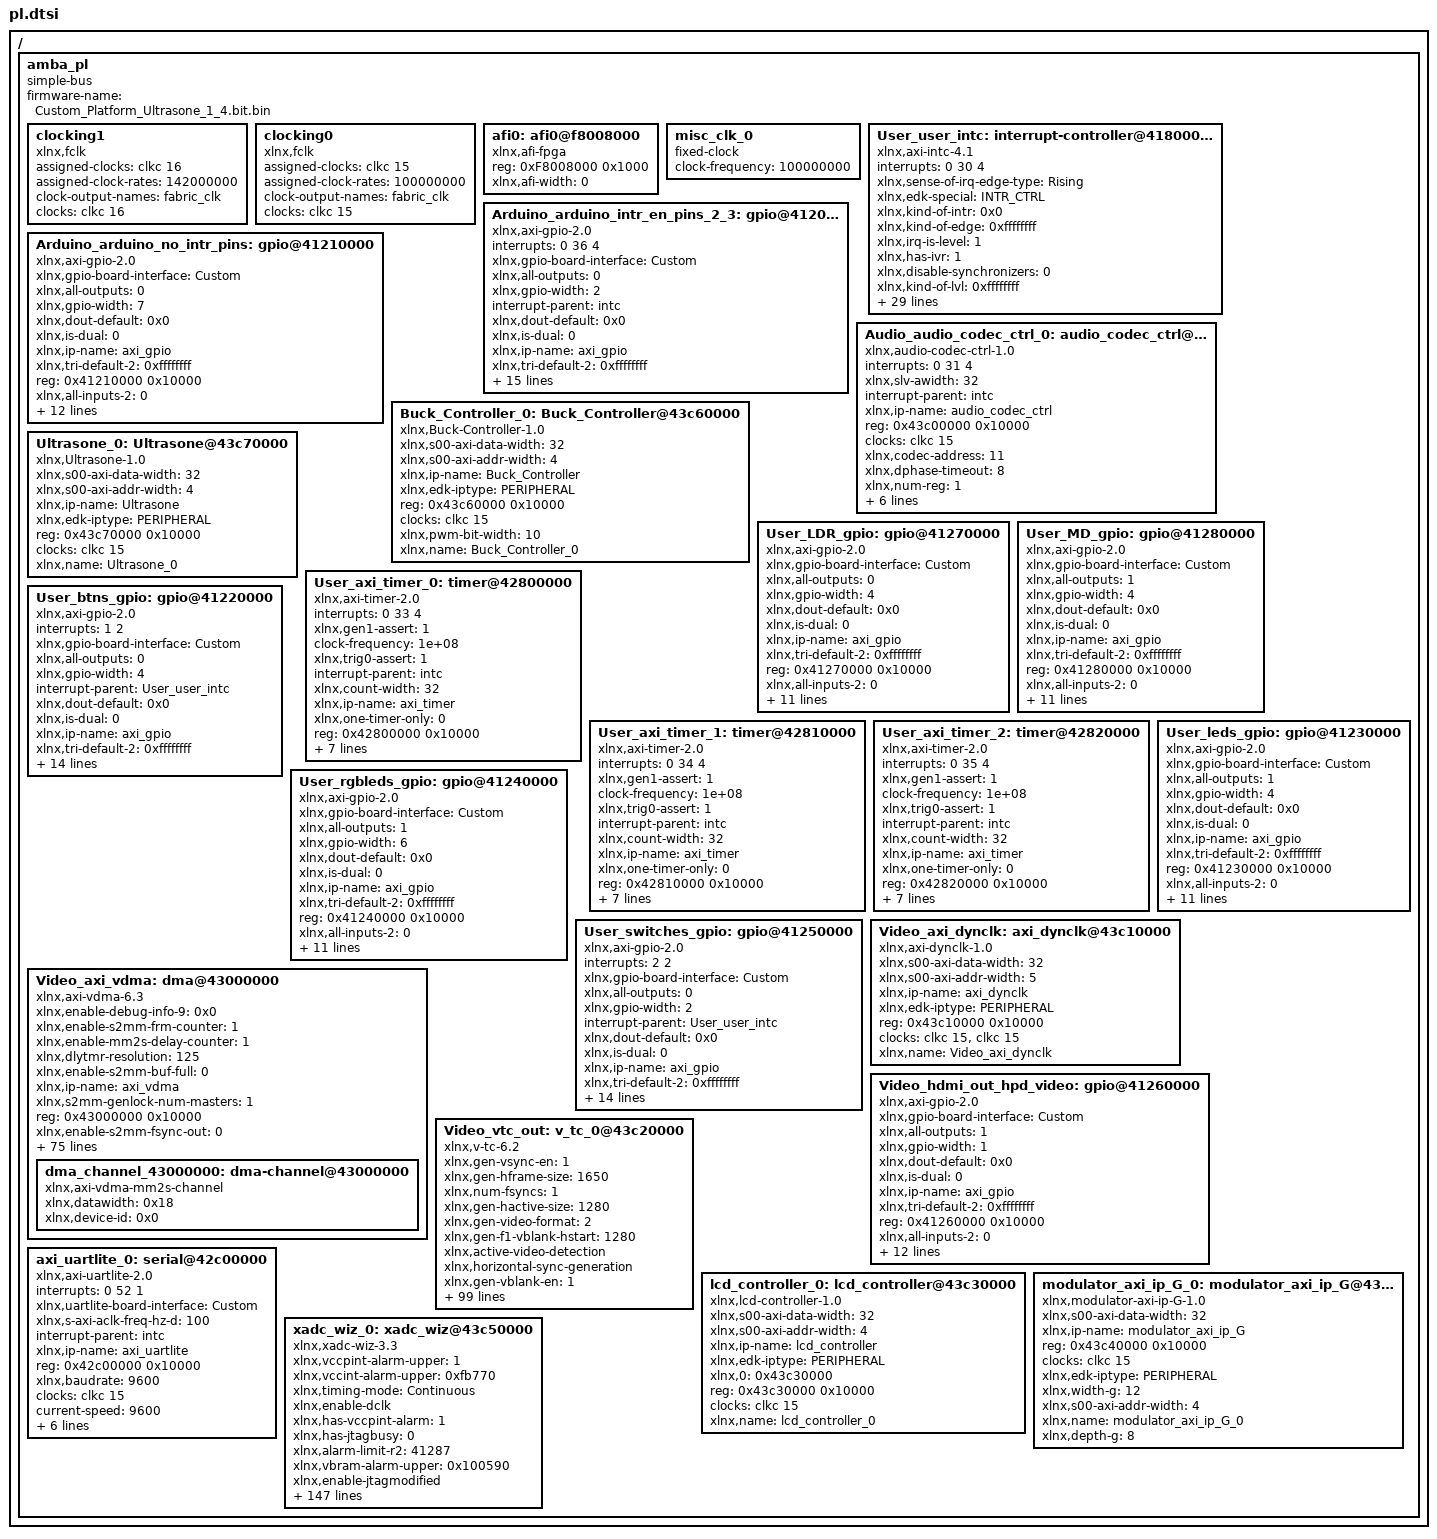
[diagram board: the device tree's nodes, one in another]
/ {
	amba_pl: amba_pl {
		ranges;
		compatible = "simple-bus";
		#address-cells = <1>;
		#size-cells = <1>;
		firmware-name = "Custom_Platform_Ultrasone_1_4.bit.bin";
		clocking1: clocking1 {
			compatible = "xlnx,fclk";
			assigned-clocks = <&clkc 16>;
			assigned-clock-rates = <142000000>;
			#clock-cells = <0>;
			clock-output-names = "fabric_clk";
			clocks = <&clkc 16>;
		};
		clocking0: clocking0 {
			compatible = "xlnx,fclk";
			assigned-clocks = <&clkc 15>;
			assigned-clock-rates = <100000000>;
			#clock-cells = <0>;
			clock-output-names = "fabric_clk";
			clocks = <&clkc 15>;
		};
		afi0: afi0@f8008000 {
			status = "okay";
			compatible = "xlnx,afi-fpga";
			#address-cells = <1>;
			reg = <0xF8008000 0x1000>;
			#size-cells = <0>;
			xlnx,afi-width = <0>;
		};
		misc_clk_0: misc_clk_0 {
			compatible = "fixed-clock";
			clock-frequency = <100000000>;
			#clock-cells = <0>;
		};
		User_user_intc: interrupt-controller@41800000 {
			#interrupt-cells = <2>;
			interrupts = < 0 30 4 >;
			xlnx,sense-of-irq-edge-type = "Rising";
			xlnx,edk-special = "INTR_CTRL";
			xlnx,kind-of-intr = <0x0>;
			xlnx,kind-of-edge = <0xffffffff>;
			xlnx,irq-is-level = <1>;
			xlnx,has-ivr = <1>;
			compatible = "xlnx,axi-intc-4.1" , "xlnx,xps-intc-1.00.a";
			xlnx,disable-synchronizers = <0>;
			xlnx,kind-of-lvl = <0xffffffff>;
			xlnx,ivar-reset-value = <0x10>;
			xlnx,irq-active = <0x1>;
			interrupt-parent = <&intc>;
			xlnx,en-cascade-mode = <0>;
			xlnx,ip-name = "axi_intc";
			xlnx,has-ilr = <0>;
			reg = <0x41800000 0x10000>;
			xlnx,addr-width = <0x20>;
			clocks = <&clkc 15>;
			xlnx,s-axi-aclk-freq-mhz = <100>;
			xlnx,num-sw-intr = <0>;
			xlnx,irq-connection = <1>;
			xlnx,num-intr-inputs = <0x3>;
			xlnx,has-sie = <1>;
			xlnx,enable-async = <0>;
			xlnx,has-cie = <1>;
			xlnx,num-sync-ff = <2>;
			xlnx,edk-iptype = "PERIPHERAL";
			xlnx,mb-clk-not-connected = <1>;
			xlnx,has-ipr = <1>;
			xlnx,sense-of-irq-level-type = "Active_High";
			xlnx,cascade-master = <0>;
			xlnx,processor-clk-freq-mhz = <100>;
			status = "okay";
			xlnx,is-fast = <0x0>;
			clock-names = "s_axi_aclk";
			xlnx,has-fast = <0>;
			xlnx,ivar-rst-val = <0x10>;
			interrupt-controller;
			interrupt-names = "irq";
			xlnx,async-intr = <0xfffffff8>;
			xlnx,name = "User_user_intc";
		};
		Arduino_arduino_intr_en_pins_2_3: gpio@41200000 {
			#interrupt-cells = <2>;
			interrupts = < 0 36 4 >;
			xlnx,gpio-board-interface = "Custom";
			compatible = "xlnx,axi-gpio-2.0" , "xlnx,xps-gpio-1.00.a";
			xlnx,all-outputs = <0>;
			#gpio-cells = <2>;
			xlnx,gpio-width = <2>;
			interrupt-parent = <&intc>;
			xlnx,dout-default = <0x0>;
			xlnx,is-dual = <0>;
			xlnx,ip-name = "axi_gpio";
			xlnx,tri-default-2 = <0xffffffff>;
			reg = <0x41200000 0x10000>;
			xlnx,all-inputs-2 = <0>;
			clocks = <&clkc 15>;
			xlnx,all-outputs-2 = <0>;
			gpio-controller;
			xlnx,interrupt-present = <1>;
			xlnx,gpio2-board-interface = "Custom";
			xlnx,edk-iptype = "PERIPHERAL";
			xlnx,dout-default-2 = <0x0>;
			status = "okay";
			xlnx,gpio2-width = <32>;
			clock-names = "s_axi_aclk";
			xlnx,use-board-flow;
			interrupt-controller;
			interrupt-names = "ip2intc_irpt";
			xlnx,tri-default = <0xffffffff>;
			xlnx,name = "Arduino_arduino_intr_en_pins_2_3";
			xlnx,all-inputs = <0>;
		};
		Arduino_arduino_no_intr_pins: gpio@41210000 {
			xlnx,gpio-board-interface = "Custom";
			compatible = "xlnx,axi-gpio-2.0" , "xlnx,xps-gpio-1.00.a";
			xlnx,all-outputs = <0>;
			#gpio-cells = <2>;
			xlnx,gpio-width = <7>;
			xlnx,dout-default = <0x0>;
			xlnx,is-dual = <0>;
			xlnx,ip-name = "axi_gpio";
			xlnx,tri-default-2 = <0xffffffff>;
			reg = <0x41210000 0x10000>;
			xlnx,all-inputs-2 = <0>;
			clocks = <&clkc 15>;
			xlnx,all-outputs-2 = <0>;
			gpio-controller;
			xlnx,interrupt-present = <0>;
			xlnx,gpio2-board-interface = "Custom";
			xlnx,edk-iptype = "PERIPHERAL";
			xlnx,dout-default-2 = <0x0>;
			status = "okay";
			xlnx,gpio2-width = <32>;
			clock-names = "s_axi_aclk";
			xlnx,use-board-flow;
			xlnx,tri-default = <0xffffffff>;
			xlnx,name = "Arduino_arduino_no_intr_pins";
			xlnx,all-inputs = <0>;
		};
		Audio_audio_codec_ctrl_0: audio_codec_ctrl@43c00000 {
			interrupts = < 0 31 4 >;
			compatible = "xlnx,audio-codec-ctrl-1.0";
			xlnx,slv-awidth = <32>;
			interrupt-parent = <&intc>;
			xlnx,ip-name = "audio_codec_ctrl";
			reg = <0x43c00000 0x10000>;
			clocks = <&clkc 15>;
			xlnx,codec-address = "11";
			xlnx,dphase-timeout = <8>;
			xlnx,num-reg = <1>;
			xlnx,s-axi-min-size = <0x1ff>;
			xlnx,edk-iptype = "PERIPHERAL";
			xlnx,use-wstrb = <0>;
			xlnx,num-mem = <1>;
			status = "okay";
			xlnx,slv-dwidth = <32>;
			clock-names = "S_AXI_ACLK";
			interrupt-names = "tx_irq";
			xlnx,name = "Audio_audio_codec_ctrl_0";
		};
		Buck_Controller_0: Buck_Controller@43c60000 {
			xlnx,s00-axi-data-width = <32>;
			compatible = "xlnx,Buck-Controller-1.0";
			status = "okay";
			clock-names = "s00_axi_aclk";
			xlnx,s00-axi-addr-width = <4>;
			xlnx,ip-name = "Buck_Controller";
			xlnx,edk-iptype = "PERIPHERAL";
			reg = <0x43c60000 0x10000>;
			clocks = <&clkc 15>;
			xlnx,pwm-bit-width = <10>;
			xlnx,name = "Buck_Controller_0";
		};
		Ultrasone_0: Ultrasone@43c70000 {
			xlnx,s00-axi-data-width = <32>;
			compatible = "xlnx,Ultrasone-1.0";
			status = "okay";
			clock-names = "s00_axi_aclk";
			xlnx,s00-axi-addr-width = <4>;
			xlnx,ip-name = "Ultrasone";
			xlnx,edk-iptype = "PERIPHERAL";
			reg = <0x43c70000 0x10000>;
			clocks = <&clkc 15>;
			xlnx,name = "Ultrasone_0";
		};
		User_LDR_gpio: gpio@41270000 {
			xlnx,gpio-board-interface = "Custom";
			compatible = "xlnx,axi-gpio-2.0" , "xlnx,xps-gpio-1.00.a";
			xlnx,all-outputs = <0>;
			#gpio-cells = <2>;
			xlnx,gpio-width = <4>;
			xlnx,dout-default = <0x0>;
			xlnx,is-dual = <0>;
			xlnx,ip-name = "axi_gpio";
			xlnx,tri-default-2 = <0xffffffff>;
			reg = <0x41270000 0x10000>;
			xlnx,all-inputs-2 = <0>;
			clocks = <&clkc 15>;
			xlnx,all-outputs-2 = <0>;
			gpio-controller;
			xlnx,interrupt-present = <0>;
			xlnx,gpio2-board-interface = "Custom";
			xlnx,edk-iptype = "PERIPHERAL";
			xlnx,dout-default-2 = <0x0>;
			status = "okay";
			xlnx,gpio2-width = <32>;
			clock-names = "s_axi_aclk";
			xlnx,tri-default = <0xffffffff>;
			xlnx,name = "User_LDR_gpio";
			xlnx,all-inputs = <1>;
		};
		User_MD_gpio: gpio@41280000 {
			xlnx,gpio-board-interface = "Custom";
			compatible = "xlnx,axi-gpio-2.0" , "xlnx,xps-gpio-1.00.a";
			xlnx,all-outputs = <1>;
			#gpio-cells = <2>;
			xlnx,gpio-width = <4>;
			xlnx,dout-default = <0x0>;
			xlnx,is-dual = <0>;
			xlnx,ip-name = "axi_gpio";
			xlnx,tri-default-2 = <0xffffffff>;
			reg = <0x41280000 0x10000>;
			xlnx,all-inputs-2 = <0>;
			clocks = <&clkc 15>;
			xlnx,all-outputs-2 = <0>;
			gpio-controller;
			xlnx,interrupt-present = <0>;
			xlnx,gpio2-board-interface = "Custom";
			xlnx,edk-iptype = "PERIPHERAL";
			xlnx,dout-default-2 = <0x0>;
			status = "okay";
			xlnx,gpio2-width = <32>;
			clock-names = "s_axi_aclk";
			xlnx,tri-default = <0xffffffff>;
			xlnx,name = "User_MD_gpio";
			xlnx,all-inputs = <0>;
		};
		User_axi_timer_0: timer@42800000 {
			interrupts = < 0 33 4 >;
			compatible = "xlnx,axi-timer-2.0" , "xlnx,xps-timer-1.00.a";
			xlnx,gen1-assert = <1>;
			clock-frequency = "1e+08";
			xlnx,trig0-assert = <1>;
			interrupt-parent = <&intc>;
			xlnx,count-width = <32>;
			xlnx,ip-name = "axi_timer";
			xlnx,one-timer-only = <0>;
			reg = <0x42800000 0x10000>;
			clocks = <&clkc 15>;
			xlnx,gen0-assert = <1>;
			xlnx,mode-64bit = <0>;
			xlnx,edk-iptype = "PERIPHERAL";
			status = "okay";
			xlnx,trig1-assert = <1>;
			clock-names = "s_axi_aclk";
			xlnx,enable-timer2 = <1>;
			interrupt-names = "interrupt";
			xlnx,name = "User_axi_timer_0";
		};
		User_axi_timer_1: timer@42810000 {
			interrupts = < 0 34 4 >;
			compatible = "xlnx,axi-timer-2.0" , "xlnx,xps-timer-1.00.a";
			xlnx,gen1-assert = <1>;
			clock-frequency = "1e+08";
			xlnx,trig0-assert = <1>;
			interrupt-parent = <&intc>;
			xlnx,count-width = <32>;
			xlnx,ip-name = "axi_timer";
			xlnx,one-timer-only = <0>;
			reg = <0x42810000 0x10000>;
			clocks = <&clkc 15>;
			xlnx,gen0-assert = <1>;
			xlnx,mode-64bit = <0>;
			xlnx,edk-iptype = "PERIPHERAL";
			status = "okay";
			xlnx,trig1-assert = <1>;
			clock-names = "s_axi_aclk";
			xlnx,enable-timer2 = <1>;
			interrupt-names = "interrupt";
			xlnx,name = "User_axi_timer_1";
		};
		User_axi_timer_2: timer@42820000 {
			interrupts = < 0 35 4 >;
			compatible = "xlnx,axi-timer-2.0" , "xlnx,xps-timer-1.00.a";
			xlnx,gen1-assert = <1>;
			clock-frequency = "1e+08";
			xlnx,trig0-assert = <1>;
			interrupt-parent = <&intc>;
			xlnx,count-width = <32>;
			xlnx,ip-name = "axi_timer";
			xlnx,one-timer-only = <0>;
			reg = <0x42820000 0x10000>;
			clocks = <&clkc 15>;
			xlnx,gen0-assert = <1>;
			xlnx,mode-64bit = <0>;
			xlnx,edk-iptype = "PERIPHERAL";
			status = "okay";
			xlnx,trig1-assert = <1>;
			clock-names = "s_axi_aclk";
			xlnx,enable-timer2 = <1>;
			interrupt-names = "interrupt";
			xlnx,name = "User_axi_timer_2";
		};
		User_btns_gpio: gpio@41220000 {
			#interrupt-cells = <2>;
			interrupts = < 1 2 >;
			xlnx,gpio-board-interface = "Custom";
			compatible = "xlnx,axi-gpio-2.0" , "xlnx,xps-gpio-1.00.a";
			xlnx,all-outputs = <0>;
			#gpio-cells = <2>;
			xlnx,gpio-width = <4>;
			interrupt-parent = <&User_user_intc>;
			xlnx,dout-default = <0x0>;
			xlnx,is-dual = <0>;
			xlnx,ip-name = "axi_gpio";
			xlnx,tri-default-2 = <0xffffffff>;
			reg = <0x41220000 0x10000>;
			xlnx,all-inputs-2 = <0>;
			clocks = <&clkc 15>;
			xlnx,all-outputs-2 = <0>;
			gpio-controller;
			xlnx,interrupt-present = <1>;
			xlnx,gpio2-board-interface = "Custom";
			xlnx,edk-iptype = "PERIPHERAL";
			xlnx,dout-default-2 = <0x0>;
			status = "okay";
			xlnx,gpio2-width = <32>;
			clock-names = "s_axi_aclk";
			interrupt-controller;
			interrupt-names = "ip2intc_irpt";
			xlnx,tri-default = <0xffffffff>;
			xlnx,name = "User_btns_gpio";
			xlnx,all-inputs = <1>;
		};
		User_leds_gpio: gpio@41230000 {
			xlnx,gpio-board-interface = "Custom";
			compatible = "xlnx,axi-gpio-2.0" , "xlnx,xps-gpio-1.00.a";
			xlnx,all-outputs = <1>;
			#gpio-cells = <2>;
			xlnx,gpio-width = <4>;
			xlnx,dout-default = <0x0>;
			xlnx,is-dual = <0>;
			xlnx,ip-name = "axi_gpio";
			xlnx,tri-default-2 = <0xffffffff>;
			reg = <0x41230000 0x10000>;
			xlnx,all-inputs-2 = <0>;
			clocks = <&clkc 15>;
			xlnx,all-outputs-2 = <0>;
			gpio-controller;
			xlnx,interrupt-present = <0>;
			xlnx,gpio2-board-interface = "Custom";
			xlnx,edk-iptype = "PERIPHERAL";
			xlnx,dout-default-2 = <0x0>;
			status = "okay";
			xlnx,gpio2-width = <32>;
			clock-names = "s_axi_aclk";
			xlnx,tri-default = <0xffffffff>;
			xlnx,name = "User_leds_gpio";
			xlnx,all-inputs = <0>;
		};
		User_rgbleds_gpio: gpio@41240000 {
			xlnx,gpio-board-interface = "Custom";
			compatible = "xlnx,axi-gpio-2.0" , "xlnx,xps-gpio-1.00.a";
			xlnx,all-outputs = <1>;
			#gpio-cells = <2>;
			xlnx,gpio-width = <6>;
			xlnx,dout-default = <0x0>;
			xlnx,is-dual = <0>;
			xlnx,ip-name = "axi_gpio";
			xlnx,tri-default-2 = <0xffffffff>;
			reg = <0x41240000 0x10000>;
			xlnx,all-inputs-2 = <0>;
			clocks = <&clkc 15>;
			xlnx,all-outputs-2 = <0>;
			gpio-controller;
			xlnx,interrupt-present = <0>;
			xlnx,gpio2-board-interface = "Custom";
			xlnx,edk-iptype = "PERIPHERAL";
			xlnx,dout-default-2 = <0x0>;
			status = "okay";
			xlnx,gpio2-width = <32>;
			clock-names = "s_axi_aclk";
			xlnx,tri-default = <0xffffffff>;
			xlnx,name = "User_rgbleds_gpio";
			xlnx,all-inputs = <0>;
		};
		User_switches_gpio: gpio@41250000 {
			#interrupt-cells = <2>;
			interrupts = < 2 2 >;
			xlnx,gpio-board-interface = "Custom";
			compatible = "xlnx,axi-gpio-2.0" , "xlnx,xps-gpio-1.00.a";
			xlnx,all-outputs = <0>;
			#gpio-cells = <2>;
			xlnx,gpio-width = <2>;
			interrupt-parent = <&User_user_intc>;
			xlnx,dout-default = <0x0>;
			xlnx,is-dual = <0>;
			xlnx,ip-name = "axi_gpio";
			xlnx,tri-default-2 = <0xffffffff>;
			reg = <0x41250000 0x10000>;
			xlnx,all-inputs-2 = <0>;
			clocks = <&clkc 15>;
			xlnx,all-outputs-2 = <0>;
			gpio-controller;
			xlnx,interrupt-present = <1>;
			xlnx,gpio2-board-interface = "Custom";
			xlnx,edk-iptype = "PERIPHERAL";
			xlnx,dout-default-2 = <0x0>;
			status = "okay";
			xlnx,gpio2-width = <32>;
			clock-names = "s_axi_aclk";
			interrupt-controller;
			interrupt-names = "ip2intc_irpt";
			xlnx,tri-default = <0xffffffff>;
			xlnx,name = "User_switches_gpio";
			xlnx,all-inputs = <1>;
		};
		Video_axi_dynclk: axi_dynclk@43c10000 {
			xlnx,s00-axi-data-width = <32>;
			compatible = "xlnx,axi-dynclk-1.0";
			status = "okay";
			clock-names = "REF_CLK_I" , "s00_axi_aclk";
			xlnx,s00-axi-addr-width = <5>;
			xlnx,ip-name = "axi_dynclk";
			xlnx,edk-iptype = "PERIPHERAL";
			reg = <0x43c10000 0x10000>;
			clocks = <&clkc 15>, <&clkc 15>;
			xlnx,name = "Video_axi_dynclk";
		};
		Video_axi_vdma: dma@43000000 {
			xlnx,enable-debug-info-9 = <0x0>;
			xlnx,enable-s2mm-frm-counter = <1>;
			xlnx,enable-mm2s-delay-counter = <1>;
			xlnx,dlytmr-resolution = <125>;
			xlnx,enable-s2mm-buf-full = <0>;
			xlnx,ip-name = "axi_vdma";
			xlnx,s2mm-genlock-num-masters = <1>;
			reg = <0x43000000 0x10000>;
			xlnx,enable-s2mm-fsync-out = <0>;
			xlnx,use-mm2s-fsync = <0>;
			xlnx,s2mm-linebuffer-thresh = <4>;
			xlnx,enable-mm2s-frm-counter = <1>;
			xlnx,m-axis-mm2s-tdata-width = <24>;
			xlnx,enable-all = <0>;
			xlnx,dynamic-resolution = <1>;
			xlnx,enable-s2mm-rst-out = <0>;
			xlnx,s2mm-sof-enable = <0x1>;
			xlnx,mm2s-genlock-num-masters = <1>;
			xlnx,enable-mm2s-fsync-out = <0>;
			xlnx,mm2s-linebuffer-thresh = <4>;
			compatible = "xlnx,axi-vdma-6.3" , "xlnx,axi-vdma-1.00.a";
			xlnx,enable-tstvec = <0>;
			xlnx,s2mm-max-burst-length = <8>;
			xlnx,enable-mm2s-rst-out = <0>;
			xlnx,mm2s-sof-enable = <1>;
			xlnx,include-s2mm-dre = <0x0>;
			xlnx,enable-s2mm-frmstr-reg = <0>;
			xlnx,m-axi-s2mm-data-width = <64>;
			xlnx,enable-s2mm-sts-reg = <0>;
			xlnx,mm2s-max-burst-length = <16>;
			status = "okay";
			xlnx,include-mm2s-dre = <0x0>;
			xlnx,name = "Video_axi_vdma";
			xlnx,enable-mm2s-frmstr-reg = <0>;
			xlnx,m-axi-mm2s-data-width = <64>;
			xlnx,flush-on-fsync = <0x1>;
			xlnx,include-s2mm-sf = <1>;
			xlnx,single-interface = <0>;
			xlnx,s2mm-linebuffer-depth = <0x200>;
			xlnx,include-s2mm = <0x0>;
			xlnx,addr-width = <32>;
			clocks = <&clkc 16>, <&clkc 16>, <&clkc 15>;
			xlnx,s-axis-s2mm-tdata-width = <32>;
			xlnx,enable-debug-info-10 = <0>;
			xlnx,addrwidth = <0x20>;
			xlnx,enable-debug-info-11 = <0>;
			xlnx,edk-iptype = "PERIPHERAL";
			xlnx,enable-debug-info-12 = <0>;
			xlnx,use-fsync = <1>;
			xlnx,s2mm-genlock-repeat-en = <1>;
			xlnx,enable-debug-info-13 = <0x0>;
			xlnx,enable-vert-flip = <0x0>;
			xlnx,include-mm2s-sf = <0>;
			xlnx,enable-debug-info-14 = <0x1>;
			xlnx,include-internal-genlock = <0x1>;
			clock-names = "m_axi_mm2s_aclk" , "m_axis_mm2s_aclk" , "s_axi_lite_aclk";
			xlnx,enable-debug-info-15 = <0x1>;
			xlnx,mm2s-linebuffer-depth = <0x1000>;
			xlnx,include-mm2s = <0x1>;
			xlnx,s2mm-genlock-mode = <0x0>;
			xlnx,flush-fsync = <0x1>;
			xlnx,select-xpm = <0>;
			xlnx,s2mm-data-width = <0x40>;
			xlnx,num-fstores = <0x3>;
			xlnx,enable-s2mm-param-updt = <0>;
			xlnx,enable-vidparam-reads = <0x1>;
			xlnx,mm2s-genlock-repeat-en = <0>;
			xlnx,prmry-is-aclk-async = <0>;
			xlnx,s2mm-tdata-width = <0x20>;
			#dma-cells = <1>;
			xlnx,enable-vidprmtr-reads = <1>;
			xlnx,mm2s-genlock-mode = <0x0>;
			xlnx,enable-debug-info-0 = <0>;
			xlnx,enable-debug-all = <0x0>;
			xlnx,enable-debug-info-1 = <0x0>;
			xlnx,mm2s-data-width = <0x40>;
			xlnx,enable-debug-info-2 = <0>;
			xlnx,enable-mm2s-param-updt = <0>;
			xlnx,enable-debug-info-3 = <0>;
			xlnx,enable-s2mm-delay-counter = <1>;
			xlnx,enable-debug-info-4 = <0>;
			xlnx,enable-debug-info-5 = <0x0>;
			xlnx,mm2s-tdata-width = <0x18>;
			xlnx,enable-debug-info-6 = <0x1>;
			xlnx,enable-debug-info-7 = <0x1>;
			xlnx,use-s2mm-fsync = <2>;
			xlnx,enable-debug-info-8 = <0>;
			xlnx,enable-mm2s-buf-empty = <0>;
			dma_channel_43000000: dma-channel@43000000 {
				xlnx,datawidth = <0x18>;
				xlnx,device-id = <0x0>;
				compatible = "xlnx,axi-vdma-mm2s-channel";
			};
		};
		Video_hdmi_out_hpd_video: gpio@41260000 {
			#interrupt-cells = <2>;
			xlnx,gpio-board-interface = "Custom";
			compatible = "xlnx,axi-gpio-2.0" , "xlnx,xps-gpio-1.00.a";
			xlnx,all-outputs = <1>;
			#gpio-cells = <2>;
			xlnx,gpio-width = <1>;
			xlnx,dout-default = <0x0>;
			xlnx,is-dual = <0>;
			xlnx,ip-name = "axi_gpio";
			xlnx,tri-default-2 = <0xffffffff>;
			reg = <0x41260000 0x10000>;
			xlnx,all-inputs-2 = <0>;
			clocks = <&clkc 15>;
			xlnx,all-outputs-2 = <0>;
			gpio-controller;
			xlnx,interrupt-present = <1>;
			xlnx,gpio2-board-interface = "Custom";
			xlnx,edk-iptype = "PERIPHERAL";
			xlnx,dout-default-2 = <0x0>;
			status = "okay";
			xlnx,gpio2-width = <32>;
			clock-names = "s_axi_aclk";
			interrupt-controller;
			xlnx,tri-default = <0xffffffff>;
			xlnx,name = "Video_hdmi_out_hpd_video";
			xlnx,all-inputs = <0>;
		};
		Video_vtc_out: v_tc_0@43c20000 {
			xlnx,gen-vsync-en = <1>;
			xlnx,gen-hframe-size = <1650>;
			xlnx,num-fsyncs = <1>;
			xlnx,gen-hactive-size = <1280>;
			xlnx,gen-video-format = <2>;
			xlnx,gen-f1-vblank-hstart = <1280>;
			xlnx,active-video-detection;
			xlnx,horizontal-sync-generation;
			xlnx,gen-vblank-en = <1>;
			xlnx,gen-avideo-en = <1>;
			xlnx,ip-name = "v_tc";
			xlnx,fsync-hstart10 = <0>;
			xlnx,max-pixels = <4096>;
			xlnx,gen-fieldid-en = <0>;
			reg = <0x43c20000 0x10000>;
			xlnx,det-vblank-en = <1>;
			xlnx,fsync-hstart11 = <0>;
			xlnx,fsync-hstart12 = <0>;
			xlnx,gen-interlaced = <0>;
			xlnx,det-avideo-en = <1>;
			xlnx,fsync-hstart13 = <0>;
			xlnx,fsync-hstart14 = <0>;
			xlnx,gen-f0-vblank-hend = <1280>;
			xlnx,fsync-hstart15 = <0>;
			xlnx,det-hsync-en = <1>;
			xlnx,enable-generation;
			xlnx,gen-avideo-polarity = <1>;
			xlnx,max-lines-per-frame = <4096>;
			xlnx,has-axi4-lite = <1>;
			compatible = "xlnx,v-tc-6.2" , "xlnx,v-tc-6.1" , "xlnx,bridge-v-tc-6.1";
			xlnx,max-clocks-per-line = <4096>;
			xlnx,gen-f0-vframe-size = <750>;
			xlnx,gen-f0-vblank-hstart = <1280>;
			xlnx,max-lines = <4096>;
			xlnx,gen-f0-vsync-vstart = <724>;
			xlnx,horizontal-blank-generation;
			xlnx,gen-hsync-end = <1430>;
			xlnx,gen-f0-vsync-hstart = <1280>;
			xlnx,gen-f1-vsync-hend = <1280>;
			xlnx,vertical-blank-detection;
			xlnx,gen-vsync-polarity = <1>;
			xlnx,fsync-vstart0 = <0>;
			xlnx,gen-hsync-polarity = <1>;
			xlnx,fsync-vstart1 = <0>;
			status = "okay";
			xlnx,fsync-vstart2 = <0>;
			xlnx,gen-hsync-start = <1390>;
			xlnx,gen-f0-vsync-vend = <729>;
			xlnx,fsync-vstart3 = <0>;
			xlnx,vertical-sync-detection;
			xlnx,frame-syncs = <1>;
			xlnx,fsync-vstart4 = <0>;
			xlnx,gen-vactive-size = <720>;
			xlnx,name = "Video_vtc_out";
			xlnx,fsync-vstart5 = <0>;
			xlnx,gen-achroma-en = <0>;
			xlnx,fsync-vstart6 = <0>;
			xlnx,det-fieldid-en = <0>;
			xlnx,fsync-vstart7 = <0>;
			xlnx,gen-hsync-en = <1>;
			xlnx,fsync-vstart8 = <0>;
			xlnx,fsync-vstart10 = <0>;
			xlnx,fsync-vstart9 = <0>;
			xlnx,fsync-vstart11 = <0>;
			xlnx,arbitrary-res-en = <0>;
			xlnx,fsync-vstart12 = <0>;
			xlnx,fsync-vstart13 = <0>;
			clocks = <&misc_clk_0>, <&clkc 15>;
			xlnx,fsync-vstart14 = <0>;
			xlnx,fsync-vstart15 = <0>;
			xlnx,gen-cparity = <0>;
			xlnx,edk-iptype = "PERIPHERAL";
			xlnx,vertical-sync-generation;
			xlnx,gen-f1-vblank-hend = <1280>;
			xlnx,det-vsync-en = <1>;
			xlnx,gen-vblank-polarity = <1>;
			xlnx,fsync-hstart0 = <0>;
			clock-names = "clk" , "s_axi_aclk";
			xlnx,interlace-en = <0>;
			xlnx,gen-auto-switch = <0>;
			xlnx,fsync-hstart1 = <0>;
			xlnx,fsync-hstart2 = <0>;
			xlnx,active-video-generation;
			xlnx,fsync-hstart3 = <0>;
			xlnx,fsync-hstart4 = <0>;
			xlnx,horizontal-blank-detection;
			xlnx,fsync-hstart5 = <0>;
			xlnx,gen-f1-vframe-size = <750>;
			xlnx,fsync-hstart6 = <0>;
			xlnx,fsync-hstart7 = <0>;
			xlnx,fsync-hstart8 = <0>;
			xlnx,gen-hblank-en = <1>;
			xlnx,fsync-hstart9 = <0>;
			xlnx,horizontal-sync-detection;
			xlnx,gen-f1-vsync-vend = <729>;
			xlnx,detect-en = <0>;
			xlnx,det-hblank-en = <1>;
			xlnx,vid-ppc = <4>;
			xlnx,has-intc-if = <0>;
			xlnx,generate-en = <1>;
			xlnx,gen-achroma-polarity = <1>;
			xlnx,sync-en = <0>;
			xlnx,det-achroma-en = <0>;
			xlnx,generator;
			xlnx,gen-f1-vsync-vstart = <724>;
			xlnx,vertical-blank-generation;
			xlnx,gen-hblank-polarity = <1>;
			xlnx,video-mode = "720p";
			xlnx,gen-fieldid-polarity = <1>;
			xlnx,gen-f1-vsync-hstart = <1280>;
			xlnx,gen-f0-vsync-hend = <1280>;
		};
		axi_uartlite_0: serial@42c00000 {
			interrupts = < 0 52 1 >;
			compatible = "xlnx,axi-uartlite-2.0" , "xlnx,xps-uartlite-1.00.a";
			xlnx,uartlite-board-interface = "Custom";
			xlnx,s-axi-aclk-freq-hz-d = <100>;
			interrupt-parent = <&intc>;
			xlnx,ip-name = "axi_uartlite";
			reg = <0x42c00000 0x10000>;
			xlnx,baudrate = <9600>;
			clocks = <&clkc 15>;
			current-speed = <9600>;
			xlnx,use-parity = <0>;
			xlnx,edk-iptype = "PERIPHERAL";
			xlnx,odd-parity = <0>;
			status = "okay";
			clock-names = "s_axi_aclk";
			interrupt-names = "interrupt";
			xlnx,name = "axi_uartlite_0";
			xlnx,data-bits = <8>;
			xlnx,parity = "No_Parity";
		};
		lcd_controller_0: lcd_controller@43c30000 {
			xlnx,s00-axi-data-width = <32>;
			compatible = "xlnx,lcd-controller-1.0";
			status = "okay";
			clock-names = "s00_axi_aclk";
			xlnx,s00-axi-addr-width = <4>;
			xlnx,ip-name = "lcd_controller";
			xlnx,edk-iptype = "PERIPHERAL";
			xlnx,0 = <0x43c30000>;
			reg = <0x43c30000 0x10000>;
			clocks = <&clkc 15>;
			xlnx,name = "lcd_controller_0";
		};
		modulator_axi_ip_G_0: modulator_axi_ip_G@43c40000 {
			compatible = "xlnx,modulator-axi-ip-G-1.0";
			xlnx,s00-axi-data-width = <32>;
			xlnx,ip-name = "modulator_axi_ip_G";
			reg = <0x43c40000 0x10000>;
			clocks = <&clkc 15>;
			xlnx,edk-iptype = "PERIPHERAL";
			xlnx,width-g = <12>;
			status = "okay";
			xlnx,s00-axi-addr-width = <4>;
			clock-names = "s00_axi_aclk";
			xlnx,name = "modulator_axi_ip_G_0";
			xlnx,depth-g = <8>;
		};
		xadc_wiz_0: xadc_wiz@43c50000 {
			xlnx,vccpint-alarm-upper = <1>;
			xlnx,vccint-alarm-upper = <0xfb770>;
			xlnx,timing-mode = "Continuous";
			xlnx,enable-dclk;
			xlnx,has-vccpint-alarm = <1>;
			xlnx,has-jtagbusy = <0>;
			xlnx,alarm-limit-r2 = <41287>;
			xlnx,vbram-alarm-upper = <0x100590>;
			xlnx,enable-jtagmodified;
			xlnx,has-vbram-alarm = <0>;
			xlnx,has-axi = <1>;
			xlnx,alarm-limit-r3 = <51763>;
			xlnx,vaux0 = <1>;
			xlnx,has-busy = <1>;
			xlnx,alarm-limit-r4 = <43322>;
			xlnx,ot-alarm;
			xlnx,enable-channel;
			xlnx,vaux1 = <1>;
			xlnx,has-vccaux-alarm = <1>;
			xlnx,alarm-limit-r5 = <21190>;
			xlnx,channel-enable-vauxp4-vauxn4;
			xlnx,dclk-frequency = <100>;
			xlnx,vaux2 = <1>;
			xlnx,alarm-limit-r6 = <38229>;
			xlnx,vaux3 = <1>;
			xlnx,has-drp = <0>;
			xlnx,ip-name = "xadc_wiz";
			xlnx,alarm-limit-r7 = <44622>;
			xlnx,channel-enable-vauxp10-vauxn10;
			xlnx,configuration-r0 = <0>;
			xlnx,vaux4 = <1>;
			xlnx,sim-file-rel-path = "./";
			reg = <0x43c50000 0x10000>;
			xlnx,alarm-limit-r8 = <22937>;
			xlnx,configuration-r1 = <8608>;
			xlnx,external-mux-channel = "VP_VN";
			xlnx,vccint-alarm;
			xlnx,temperature-alarm-trigger = <85>;
			xlnx,vaux5 = <1>;
			xlnx,has-jtaglocked = <0>;
			xlnx,alarm-limit-r9 = <20753>;
			xlnx,channel-enable-vauxp11-vauxn11;
			xlnx,configuration-r2 = <1024>;
			xlnx,vaux6 = <1>;
			xlnx,vaux7 = <1>;
			xlnx,channel-enable-vauxp3-vauxn3;
			xlnx,user-temp-alarm;
			xlnx,vaux8 = <1>;
			xlnx,vaux9 = <1>;
			xlnx,vaux10 = <1>;
			xlnx,has-vn = <1>;
			xlnx,has-vccpaux-alarm = <1>;
			xlnx,acquisition-time = <4>;
			xlnx,channel-enable-vauxp13-vauxn13;
			xlnx,vaux11 = <1>;
			xlnx,has-temp-bus = <0>;
			xlnx,xadc-starup-selection = "channel_sequencer";
			xlnx,enable-busy;
			xlnx,data-width = <32>;
			xlnx,vaux12 = <0>;
			xlnx,sim-file-sel = "Default";
			xlnx,has-vp = <1>;
			xlnx,channel-enable-vauxp14-vauxn14;
			xlnx,ip-type = <0x0>;
			interrupt-names = "ip2intc_irpt";
			xlnx,temperature-alarm-ot-reset = <70>;
			xlnx,vaux13 = <1>;
			xlnx,enable-convst;
			xlnx,vaux14 = <1>;
			xlnx,channel-enable-vauxp15-vauxn15;
			xlnx,channel-enable-vauxp2-vauxn2;
			xlnx,channel-enable-vp-vn;
			xlnx,vccpaux-alarm-lower = <0x1a17b0>;
			xlnx,vccaux-alarm-lower = <0x1ab3f0>;
			xlnx,vaux15 = <1>;
			compatible = "xlnx,xadc-wiz-3.3" , "xlnx,axi-xadc-1.00.a";
			xlnx,has-external-mux = <0>;
			xlnx,vccaux-alarm;
			xlnx,sampling-rate = <0x7fffffff>;
			xlnx,has-reset = <0>;
			xlnx,adc-conversion-rate = <1000>;
			xlnx,vccddro-alarm-lower = <0x124f80>;
			xlnx,enable-calibration-averaging;
			xlnx,has-user-temp-alarm = <1>;
			interrupt-parent = <&intc>;
			xlnx,has-ot-alarm = <1>;
			xlnx,has-convst = <0>;
			xlnx,channel-enable-vauxp1-vauxn1;
			xlnx,single-channel-selection = "TEMPERATURE";
			xlnx,startup-channel-selection = "single_channel";
			xlnx,interface-selection = "Enable_AXI";
			xlnx,vccpaux-alarm-upper = <0x1b7740>;
			xlnx,vccaux-alarm-upper = <0x1cd6d0>;
			xlnx,channel-enable-vauxp0-vauxn0;
			status = "okay";
			xlnx,sensor-offset-and-gain-calibration;
			xlnx,vccddro-alarm-upper = <0x1312d0>;
			xlnx,name = "xadc_wiz_0";
			xlnx,external-mux = "none";
			interrupts = < 0 32 4 >;
			xlnx,enable-vccddro-alarm;
			xlnx,enable-eoc;
			xlnx,enable-jtaglocked;
			xlnx,sim-file-name = "design";
			xlnx,enable-vccpint-alarm;
			xlnx,channel-enable-vauxp9-vauxn9;
			xlnx,temperature-alarm-reset = <60>;
			xlnx,addr-width = <32>;
			clocks = <&clkc 15>;
			xlnx,alarm-limit-r10 = <21845>;
			xlnx,alarm-limit-r11 = <20753>;
			xlnx,alarm-limit-r12 = <39321>;
			xlnx,edk-iptype = "PERIPHERAL";
			xlnx,alarm-limit-r13 = <37355>;
			xlnx,sequencer-mode = "Continuous";
			xlnx,enable-jtagbusy;
			xlnx,alarm-limit-r14 = <27306>;
			xlnx,channel-enable-vauxp8-vauxn8;
			xlnx,include-intr = <1>;
			xlnx,fifo-depth = <7>;
			xlnx,alarm-limit-r15 = <26214>;
			clock-names = "s_axi_aclk";
			xlnx,enable-vccpaux-alarm;
			xlnx,has-eoc = <1>;
			xlnx,temperature-alarm-ot-trigger = <125>;
			xlnx,has-channel = <1>;
			xlnx,enable-eos;
			xlnx,channel-enable-vauxp7-vauxn7;
			xlnx,vccpint-alarm-lower = <0xe7ef0>;
			xlnx,vccint-alarm-lower = <0xecd10>;
			xlnx,has-dclk = <1>;
			xlnx,vbram-alarm-lower = <0xe7ef0>;
			xlnx,num-wave = <1>;
			xlnx,sequence-r0 = <2048>;
			xlnx,has-jtagmodified = <0>;
			xlnx,sequence-r1 = <61439>;
			xlnx,channel-enable-vauxp6-vauxn6;
			xlnx,enable-drp;
			xlnx,sequence-r2 = <0>;
			xlnx,has-vccint-alarm = <1>;
			xlnx,channel-averaging = "None";
			xlnx,sequence-r3 = <0>;
			xlnx,has-axi4stream = <0>;
			xlnx,sequence-r4 = <0>;
			xlnx,sequence-r5 = <0>;
			xlnx,adc-offset-and-gain-calibration;
			xlnx,waveform-type = "CONSTANT";
			xlnx,sequence-r6 = <0>;
			xlnx,vccddro-volt = "1_2";
			xlnx,sequence-r7 = <0>;
			xlnx,channel-enable-vauxp5-vauxn5;
			xlnx,has-vccddro-alarm = <1>;
			xlnx,has-eos = <1>;
			xlnx,has-convstclk = <0>;
			xlnx,alarm-limit-r0 = <46573>;
			xlnx,stimulus-freq = <1>;
			xlnx,single-channel-enable-calibration;
			xlnx,external-muxaddr-enable = <0>;
			xlnx,alarm-limit-r1 = <22500>;
			xlnx,component-name = "system_xadc_wiz_0_0";
		};
	};
};
